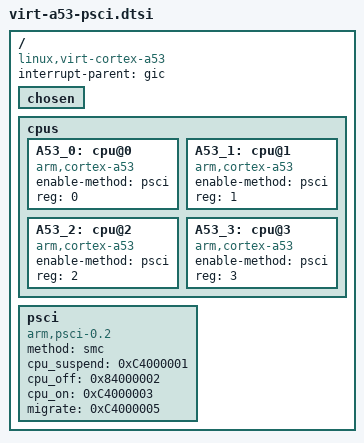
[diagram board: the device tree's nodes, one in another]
/dts-v1/;

/ {
	compatible = "linux,virt-cortex-a53";
	interrupt-parent = <&gic>;
	#size-cells = <2>;
	#address-cells = <2>;


	chosen {};

	cpus {
		#size-cells = <0>;
		#address-cells = <1>;


		A53_0: cpu@0 {
			device_type = "cpu";
			compatible = "arm,cortex-a53";
			enable-method = "psci";
			reg = <0>;
		};

		A53_1: cpu@1 {
			device_type = "cpu";
			compatible = "arm,cortex-a53";
			enable-method = "psci";
			reg = <1>;
		};

		A53_2: cpu@2 {
			device_type = "cpu";
			compatible = "arm,cortex-a53";
			enable-method = "psci";
			reg = <2>;
		};

		A53_3: cpu@3 {
			device_type = "cpu";
			compatible = "arm,cortex-a53";
			enable-method = "psci";
			reg = <3>;
		};

	};

	psci {
		compatible = "arm,psci-0.2", "arm,psci";
		method = "smc";
		cpu_suspend = <0xC4000001>;
                cpu_off = <0x84000002>;
                cpu_on = <0xC4000003>;
		migrate = <0xC4000005>;
        };
};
